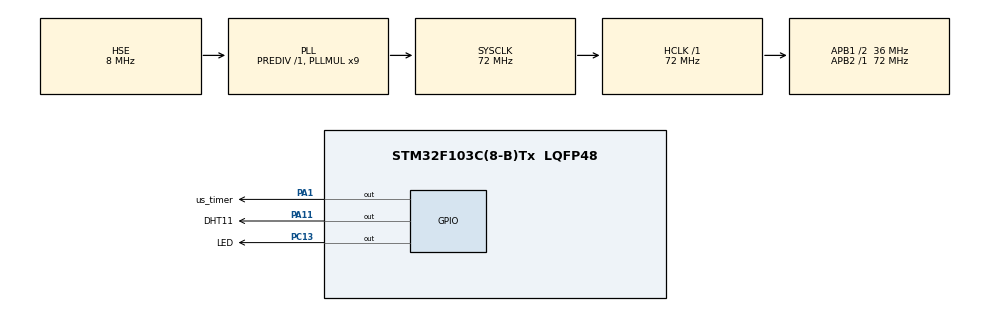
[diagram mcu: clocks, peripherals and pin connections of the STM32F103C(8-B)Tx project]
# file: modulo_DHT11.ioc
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Mcu.Family=STM32F1
RCC.PLLSourceVirtual=RCC_PLLSOURCE_HSE
PD1-OSC_OUT.Mode=HSE-External-Oscillator
PC13-TAMPER-RTC.Signal=GPIO_Output
PA11.GPIO_Label=DHT11
PD0-OSC_IN.Signal=RCC_OSC_IN
RCC.APB1CLKDivider=RCC_HCLK_DIV2
RCC.SYSCLKSource=RCC_SYSCLKSOURCE_PLLCLK
ProjectManager.StackSize=0x400
PD1-OSC_OUT.Signal=RCC_OSC_OUT
PA13.Signal=SYS_JTMS-SWDIO
TIM1.Prescaler=72-1
ProjectManager.TargetToolchain=STM32CubeIDE
RCC.HCLKFreq_Value=72000000
RCC.APB2TimFreq_Value=72000000
RCC.USBFreq_Value=72000000
PA1.Signal=GPIO_Output
RCC.AHBFreq_Value=72000000
PD0-OSC_IN.Mode=HSE-External-Oscillator
board=custom
RCC.PLLMUL=RCC_PLL_MUL9
PC13-TAMPER-RTC.GPIO_Label=LED
RCC.APB2Freq_Value=72000000
PA14.Mode=Serial_Wire
PA1.GPIO_Label=us_timer
PA13.Mode=Serial_Wire
Mcu.Name=STM32F103C(8-B)Tx
VP_TIM1_VS_ClockSourceINT.Mode=Internal
RCC.SYSCLKFreq_VALUE=72000000
Mcu.Package=LQFP48
PA11.Signal=GPIO_Output
PA14.Signal=SYS_JTCK-SWCLK
ProjectManager.HeapSize=0x200
NVIC.PriorityGroup=NVIC_PRIORITYGROUP_4
RCC.APB1TimFreq_Value=72000000
TIM1.Period=0xFFFF-1
RCC.APB1Freq_Value=36000000

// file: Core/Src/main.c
/* USER CODE BEGIN Header */
/**
  ******************************************************************************
  * @file           : main.c
  * @brief          : Main program body
  ******************************************************************************
  * @attention
  *
  * <h2><center>&copy; Copyright (c) 2025 STMicroelectronics.
  * All rights reserved.</center></h2>
  *
  * This software component is licensed by ST under BSD 3-Clause license,
  * the "License"; You may not use this file except in compliance with the
  * License. You may obtain a copy of the License at:
  *                        opensource.org/licenses/BSD-3-Clause
  *
  ******************************************************************************
  */
/* USER CODE END Header */
#include "main.h"
#include "dht11.h"
#include <string.h>
#include <stdio.h>

TIM_HandleTypeDef htim1;

void SystemClock_Config(void);
static void MX_GPIO_Init(void);
static void MX_TIM1_Init(void);

/* USER CODE BEGIN 0 */
void delay_us (uint16_t us)
{
	__HAL_TIM_SET_COUNTER(&htim1,0);  // set the counter value a 0
	while (__HAL_TIM_GET_COUNTER(&htim1) < us);// wait for the counter to reach the us input in the parameter
}
/* USER CODE END 0 */

int main(void)
{

  /* MCU Configuration--------------------------------------------------------*/

  /* Reset of all peripherals, Initializes the Flash interface and the Systick. */
  HAL_Init();

  /* Configure the system clock */
  SystemClock_Config();

  /* Initialize all configured peripherals */
  MX_GPIO_Init();
  MX_TIM1_Init();

  /* Infinite loop */
  /* USER CODE BEGIN WHILE */
  DHT11_Init();
  uint32_t humedad = 0;
  uint32_t temperatura = 0;

  while (1)
  {
	  //HAL_Delay(1000);
	  //HAL_GPIO_TogglePin(LED_GPIO_Port, LED_Pin);
	  /*Anda pero es ULTRA sensible a cualquier interrupcion
	   * hay que empechugarlo mas
	   * pero anda*/
	  humedad = DHT11_GetHumedad();
    /* USER CODE END WHILE */

  }
}

void SystemClock_Config(void)
{
  RCC_OscInitTypeDef RCC_OscInitStruct = {0};
  RCC_ClkInitTypeDef RCC_ClkInitStruct = {0};

  /** Initializes the RCC Oscillators according to the specified parameters
  * in the RCC_OscInitTypeDef structure.
  */
  RCC_OscInitStruct.OscillatorType = RCC_OSCILLATORTYPE_HSE;
  RCC_OscInitStruct.HSEState = RCC_HSE_ON;
  RCC_OscInitStruct.HSEPredivValue = RCC_HSE_PREDIV_DIV1;
  RCC_OscInitStruct.HSIState = RCC_HSI_ON;
  RCC_OscInitStruct.PLL.PLLState = RCC_PLL_ON;
  RCC_OscInitStruct.PLL.PLLSource = RCC_PLLSOURCE_HSE;
  RCC_OscInitStruct.PLL.PLLMUL = RCC_PLL_MUL9;
  if (HAL_RCC_OscConfig(&RCC_OscInitStruct) != HAL_OK)
  {
    Error_Handler();
  }
  /** Initializes the CPU, AHB and APB buses clocks
  */
  RCC_ClkInitStruct.ClockType = RCC_CLOCKTYPE_HCLK|RCC_CLOCKTYPE_SYSCLK
                              |RCC_CLOCKTYPE_PCLK1|RCC_CLOCKTYPE_PCLK2;
  RCC_ClkInitStruct.SYSCLKSource = RCC_SYSCLKSOURCE_PLLCLK;
  RCC_ClkInitStruct.AHBCLKDivider = RCC_SYSCLK_DIV1;
  RCC_ClkInitStruct.APB1CLKDivider = RCC_HCLK_DIV2;
  RCC_ClkInitStruct.APB2CLKDivider = RCC_HCLK_DIV1;

  if (HAL_RCC_ClockConfig(&RCC_ClkInitStruct, FLASH_LATENCY_2) != HAL_OK)
  {
    Error_Handler();
  }
}

static void MX_TIM1_Init(void)
{

  TIM_ClockConfigTypeDef sClockSourceConfig = {0};
  TIM_MasterConfigTypeDef sMasterConfig = {0};

  htim1.Instance = TIM1;
  htim1.Init.Prescaler = 72-1;
  htim1.Init.CounterMode = TIM_COUNTERMODE_UP;
  htim1.Init.Period = 0xFFFF-1;
  htim1.Init.ClockDivision = TIM_CLOCKDIVISION_DIV1;
  htim1.Init.RepetitionCounter = 0;
  htim1.Init.AutoReloadPreload = TIM_AUTORELOAD_PRELOAD_DISABLE;
  if (HAL_TIM_Base_Init(&htim1) != HAL_OK)
  {
    Error_Handler();
  }
  sClockSourceConfig.ClockSource = TIM_CLOCKSOURCE_INTERNAL;
  if (HAL_TIM_ConfigClockSource(&htim1, &sClockSourceConfig) != HAL_OK)
  {
    Error_Handler();
  }
  sMasterConfig.MasterOutputTrigger = TIM_TRGO_RESET;
  sMasterConfig.MasterSlaveMode = TIM_MASTERSLAVEMODE_DISABLE;
  if (HAL_TIMEx_MasterConfigSynchronization(&htim1, &sMasterConfig) != HAL_OK)
  {
    Error_Handler();
  }

}

static void MX_GPIO_Init(void)
{
  GPIO_InitTypeDef GPIO_InitStruct = {0};

  /* GPIO Ports Clock Enable */
  __HAL_RCC_GPIOC_CLK_ENABLE();
  __HAL_RCC_GPIOD_CLK_ENABLE();
  __HAL_RCC_GPIOA_CLK_ENABLE();

  /*Configure GPIO pin Output Level */
  HAL_GPIO_WritePin(LED_GPIO_Port, LED_Pin, GPIO_PIN_RESET);

  /*Configure GPIO pin Output Level */
  HAL_GPIO_WritePin(GPIOA, us_timer_Pin|DHT11_Pin, GPIO_PIN_RESET);

  /*Configure GPIO pin : LED_Pin */
  GPIO_InitStruct.Pin = LED_Pin;
  GPIO_InitStruct.Mode = GPIO_MODE_OUTPUT_PP;
  GPIO_InitStruct.Pull = GPIO_NOPULL;
  GPIO_InitStruct.Speed = GPIO_SPEED_FREQ_LOW;
  HAL_GPIO_Init(LED_GPIO_Port, &GPIO_InitStruct);

  /*Configure GPIO pins : us_timer_Pin DHT11_Pin */
  GPIO_InitStruct.Pin = us_timer_Pin|DHT11_Pin;
  GPIO_InitStruct.Mode = GPIO_MODE_OUTPUT_PP;
  GPIO_InitStruct.Pull = GPIO_NOPULL;
  GPIO_InitStruct.Speed = GPIO_SPEED_FREQ_LOW;
  HAL_GPIO_Init(GPIOA, &GPIO_InitStruct);

}

void Error_Handler(void)
{
  __disable_irq();
  while (1)
  {
  }
}

/************************ (C) COPYRIGHT STMicroelectronics *****END OF FILE****/
